AUTOSAR XML (schema 4-0-3)
package /ComponentTypes
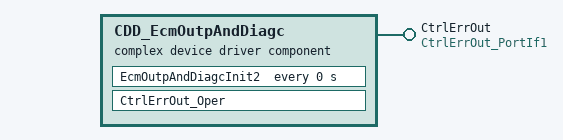
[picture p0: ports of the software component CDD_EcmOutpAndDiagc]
  complex device driver sw component type CDD_EcmOutpAndDiagc
    provide port CtrlErrOut: server-com-spec{operation=Oper, queue-length=1}, provided-interface=CtrlErrOut_PortIf1
    behavior CDD_EcmOutpAndDiagc_InternalBehavior
      ar-typed-per-instance-memorys:
        data dEcmVrfyErrOutpCtrlCmpl: sw-calibration-access=READ-ONLY, type=boolean
        data dEcmVrfyIntrptGennCmpl: sw-calibration-access=READ-ONLY, type=boolean
      operation invoked event OIT_CtrlErrOut_Oper_CtrlErrOut_Oper: start-on-event=CtrlErrOut_Oper, operation=CtrlErrOut.Oper
      timing event CDD_EcmOutpAndDiagc_InitEvent: start-on-event=EcmOutpAndDiagcInit2, period=0
      runnable CtrlErrOut_Oper
      runnable EcmOutpAndDiagcInit2
  swc implementation CDD_EcmOutpAndDiagc_Implementation: behavior=CDD_EcmOutpAndDiagc_InternalBehavior
    code-descriptors:
      code Default: artifact-descriptors=autosar-engineering-object={short-label=Default, category=SWSRC}
